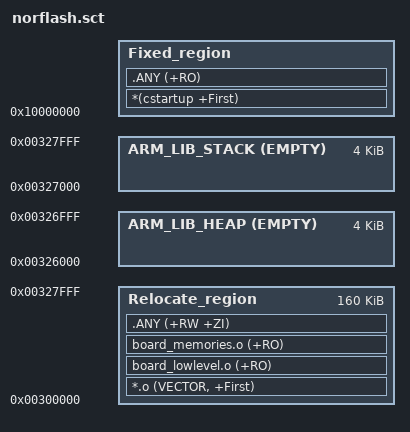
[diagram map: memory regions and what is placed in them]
; * ----------------------------------------------------------------------------
; *         ATMEL Microcontroller Software Support 
; * ----------------------------------------------------------------------------
; * Copyright (c) 2008, Atmel Corporation
; *
; * All rights reserved.
; *
; * Redistribution and use in source and binary forms, with or without
; * modification, are permitted provided that the following conditions are met:
; *
; * - Redistributions of source code must retain the above copyright notice,
; * this list of conditions and the disclaimer below.
; *
; * Atmel's name may not be used to endorse or promote products derived from
; * this software without specific prior written permission.
; *
; * DISCLAIMER: THIS SOFTWARE IS PROVIDED BY ATMEL "AS IS" AND ANY EXPRESS OR
; * IMPLIED WARRANTIES, INCLUDING, BUT NOT LIMITED TO, THE IMPLIED WARRANTIES OF
; * MERCHANTABILITY, FITNESS FOR A PARTICULAR PURPOSE AND NON-INFRINGEMENT ARE
; * DISCLAIMED. IN NO EVENT SHALL ATMEL BE LIABLE FOR ANY DIRECT, INDIRECT,
; * INCIDENTAL, SPECIAL, EXEMPLARY, OR CONSEQUENTIAL DAMAGES (INCLUDING, BUT NOT
; * LIMITED TO, PROCUREMENT OF SUBSTITUTE GOODS OR SERVICES; LOSS OF USE, DATA,
; * OR PROFITS; OR BUSINESS INTERRUPTION) HOWEVER CAUSED AND ON ANY THEORY OF
; * LIABILITY, WHETHER IN CONTRACT, STRICT LIABILITY, OR TORT (INCLUDING
; * NEGLIGENCE OR OTHERWISE) ARISING IN ANY WAY OUT OF THE USE OF THIS SOFTWARE,
; * EVEN IF ADVISED OF THE POSSIBILITY OF SUCH DAMAGE.
; * ----------------------------------------------------------------------------

; *------------------------------------------------------------------------------
; *      Linker scatter for running in norflash on the AT91SAM9261
; *----------------------------------------------------------------------------*/

Load_region 0x10000000 0x10000000 {

    Fixed_region 0x10000000 {
       *(cstartup +First)
       .ANY (+RO)
    }
   
    Relocate_region 0x300000 0x28000 {
        *.o (VECTOR, +First)   
        board_lowlevel.o (+RO)
        board_memories.o (+RO)
        .ANY (+RW +ZI)
    }
    
    ARM_LIB_HEAP 0x326000 EMPTY 0x1000 {
    }
    
    ARM_LIB_STACK 0x328000 EMPTY -0x1000 {
    }
    
}
